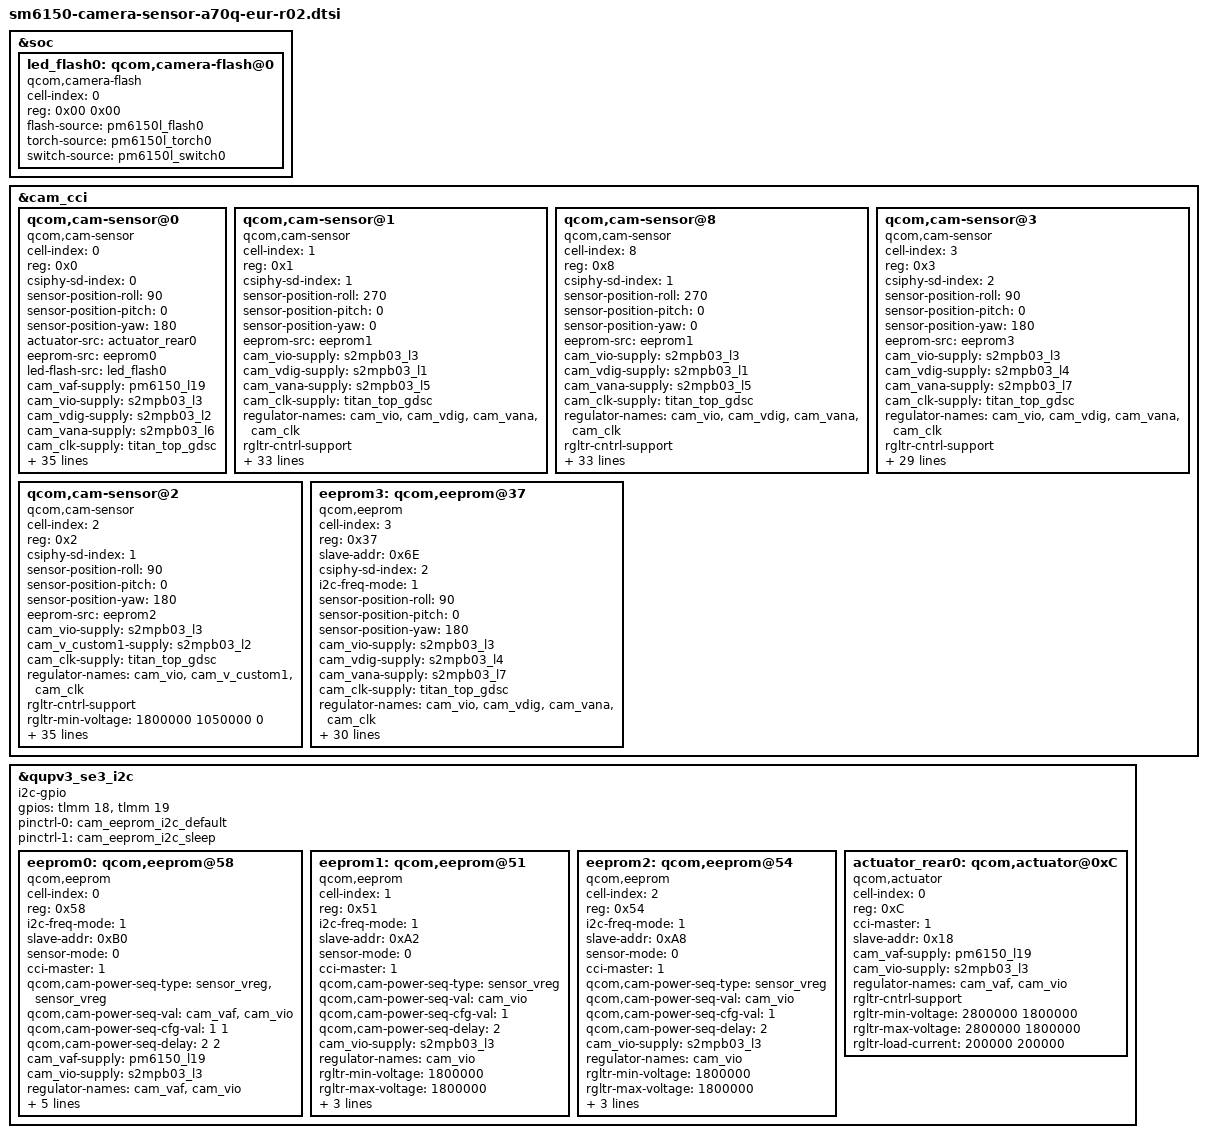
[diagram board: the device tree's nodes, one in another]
&soc {
        led_flash0: qcom,camera-flash@0 {
              cell-index = <0>;
              reg = <0x00 0x00>;
              compatible = "qcom,camera-flash";
              flash-source = <&pm6150l_flash0>;
              torch-source = <&pm6150l_torch0>;
              switch-source = <&pm6150l_switch0>;		
              status = "ok";
        };
};

&cam_cci{
		qcom,cam-sensor@0 {
			cell-index = <0>;
			compatible = "qcom,cam-sensor";
			reg = <0x0>;
			csiphy-sd-index = <0>;
			sensor-position-roll = <90>;
			sensor-position-pitch = <0>;
			sensor-position-yaw = <180>;
			actuator-src = <&actuator_rear0>;
			eeprom-src = <&eeprom0>;  
			led-flash-src = <&led_flash0>;
			cam_vaf-supply = <&pm6150_l19>;
			cam_vio-supply = <&s2mpb03_l3>;
			cam_vdig-supply = <&s2mpb03_l2>;
			cam_vana-supply = <&s2mpb03_l6>;
			cam_clk-supply = <&titan_top_gdsc>; 
			regulator-names = "cam_vaf", "cam_vio", "cam_vdig", "cam_vana", "cam_clk";
			rgltr-cntrl-support;
			rgltr-min-voltage = <2800000 1800000 1050000 2800000 0>;
			rgltr-max-voltage = <2800000 1800000 1050000 2800000 0>;
			rgltr-load-current = <200000 200000 200000 200000 0>;
			gpio-no-mux = <0>;
			pinctrl-names = "cam_default", "cam_suspend";
			pinctrl-0 = <&cam_sensor_mclk_0_active &cam_sensor_rear_active>;
			pinctrl-1 = <&cam_sensor_mclk_0_suspend &cam_sensor_rear_suspend>;
			gpios = <&tlmm 28 0>,
					<&tlmm 47 0>;
			gpio-reset = <1>;
			gpio-req-tbl-num = <0 1>;
			gpio-req-tbl-flags = <1 0>;
			gpio-req-tbl-label = "CAMIF_MCLK0", "CAM_RESET0";

			sensor-mode = <0>;
			cci-master = <0>;
			status = "ok";
			clocks = <&clock_camcc CAM_CC_MCLK0_CLK>;
			clock-names = "cam_clk";
			clock-cntl-level = "turbo";
			clock-rates = <24000000>;

			cam,isp = <0>;                  // 0 : INT , 1 : EXT , 2 : SOC
			cam,cal_memory = <2>;           // 0 : N , 1 : FROM , 2 : EEPROM , 3 : OTP
			cam,read_version = <0>;         // 0 : SYSFS , 1 : CAMON
			cam,core_voltage = <0>;         // 0 : N , 1 : Y
			cam,upgrade = <0>;              // 0 : N , 1 : SYSFS , 2 : CAMON
			cam,fw_write = <0>;             // 0 : N , 1 : OS , 2 : SD , 3 : ALL
			cam,fw_dump = <0>;              // 0 : N , 1 : Y
			cam,companion_chip = <0>;       // 0 : N , 1 : Y
			cam,ois = <0>;                  // 0 : N , 1 : Y
			cam,dual_open = <0>;            // 0 : N , 1 : Y
			cam,valid = <1>;                // 0 : N , 1 : Y
        };
		qcom,cam-sensor@1 {
			cell-index = <1>;
			compatible = "qcom,cam-sensor";
			reg = <0x1>;
			csiphy-sd-index = <1>;
			sensor-position-roll = <270>;
			sensor-position-pitch = <0>;
			sensor-position-yaw = <0>;
			eeprom-src = <&eeprom1>;
			cam_vio-supply = <&s2mpb03_l3>;
			cam_vdig-supply = <&s2mpb03_l1>;
			cam_vana-supply = <&s2mpb03_l5>;
			cam_clk-supply = <&titan_top_gdsc>; 
			regulator-names = "cam_vio", "cam_vdig", "cam_vana", "cam_clk";
			rgltr-cntrl-support;
			rgltr-min-voltage = <1800000 1050000 2800000 0>;
			rgltr-max-voltage = <1800000 1050000 2800000 0>;
			rgltr-load-current = <200000 200000 200000 0>;
			gpio-no-mux = <0>;
			pinctrl-names = "cam_default", "cam_suspend";
			pinctrl-0 = <&cam_sensor_mclk_1_active &cam_sensor_front_active &cam_sensor_mipi_sw_active>;
			pinctrl-1 = <&cam_sensor_mclk_1_suspend &cam_sensor_front_suspend &cam_sensor_mipi_sw_suspend>;
			gpios = <&tlmm 29 0>,
					<&tlmm 45 0>,
					<&tlmm 49 0>;
			gpio-reset = <1>;
			gpio-custom1 = <2>;
			gpio-req-tbl-num = <0 1 2>;
			gpio-req-tbl-flags = <1 0 0>;
			gpio-req-tbl-label = "CAMIF_MCLK1", "CAM_RESET1", "CAM_CUSTOM1";

			sensor-mode = <0>;
			cci-master = <1>;
			status = "ok";
			clocks = <&clock_camcc CAM_CC_MCLK1_CLK>;
			clock-names = "cam_clk";
			clock-cntl-level = "turbo";
			clock-rates = <24000000>;

			cam,isp = <0>;                  // 0 : INT , 1 : EXT , 2 : SOC
			cam,cal_memory = <2>;           // 0 : N , 1 : FROM , 2 : EEPROM , 3 : OTP
			cam,read_version = <0>;         // 0 : SYSFS , 1 : CAMON
			cam,core_voltage = <0>;         // 0 : N , 1 : Y
			cam,upgrade = <0>;              // 0 : N , 1 : SYSFS , 2 : CAMON
			cam,fw_write = <0>;             // 0 : N , 1 : OS , 2 : SD , 3 : ALL
			cam,fw_dump = <0>;              // 0 : N , 1 : Y
			cam,companion_chip = <0>;       // 0 : N , 1 : Y
			cam,ois = <0>;                  // 0 : N , 1 : Y
			cam,dual_open = <0>;            // 0 : N , 1 : Y
			cam,valid = <1>;                // 0 : N , 1 : Y
        };

		qcom,cam-sensor@8 {
			cell-index = <8>;
			compatible = "qcom,cam-sensor";
			reg = <0x8>;
			csiphy-sd-index = <1>;
			sensor-position-roll = <270>;
			sensor-position-pitch = <0>;
			sensor-position-yaw = <0>;
			eeprom-src = <&eeprom1>;
			cam_vio-supply = <&s2mpb03_l3>;
			cam_vdig-supply = <&s2mpb03_l1>;
			cam_vana-supply = <&s2mpb03_l5>;
			cam_clk-supply = <&titan_top_gdsc>; 
			regulator-names = "cam_vio", "cam_vdig", "cam_vana", "cam_clk";
			rgltr-cntrl-support;
			rgltr-min-voltage = <1800000 1050000 2800000 0>;
			rgltr-max-voltage = <1800000 1050000 2800000 0>;
			rgltr-load-current = <200000 200000 200000 0>;
			gpio-no-mux = <0>;
			pinctrl-names = "cam_default", "cam_suspend";
			pinctrl-0 = <&cam_sensor_mclk_1_active &cam_sensor_front_active &cam_sensor_mipi_sw_active>;
			pinctrl-1 = <&cam_sensor_mclk_1_suspend &cam_sensor_front_suspend &cam_sensor_mipi_sw_suspend>;
			gpios = <&tlmm 29 0>,
					<&tlmm 45 0>,
					<&tlmm 49 0>;
			gpio-reset = <1>;
			gpio-custom1 = <2>;
			gpio-req-tbl-num = <0 1 2>;
			gpio-req-tbl-flags = <1 0 0>;
			gpio-req-tbl-label = "CAMIF_MCLK1", "CAM_RESET1", "CAM_CUSTOM1";

			sensor-mode = <0>;
			cci-master = <1>;
			status = "ok";
			clocks = <&clock_camcc CAM_CC_MCLK1_CLK>;
			clock-names = "cam_clk";
			clock-cntl-level = "turbo";
			clock-rates = <24000000>;

			cam,isp = <0>;                  // 0 : INT , 1 : EXT , 2 : SOC
			cam,cal_memory = <2>;           // 0 : N , 1 : FROM , 2 : EEPROM , 3 : OTP
			cam,read_version = <0>;         // 0 : SYSFS , 1 : CAMON
			cam,core_voltage = <0>;         // 0 : N , 1 : Y
			cam,upgrade = <0>;              // 0 : N , 1 : SYSFS , 2 : CAMON
			cam,fw_write = <0>;             // 0 : N , 1 : OS , 2 : SD , 3 : ALL
			cam,fw_dump = <0>;              // 0 : N , 1 : Y
			cam,companion_chip = <0>;       // 0 : N , 1 : Y
			cam,ois = <0>;                  // 0 : N , 1 : Y
			cam,dual_open = <0>;            // 0 : N , 1 : Y
			cam,valid = <1>;                // 0 : N , 1 : Y
        };
		
		qcom,cam-sensor@3 {
			cell-index = <3>;
			compatible = "qcom,cam-sensor";
			reg = <0x3>;
			csiphy-sd-index = <2>;
			sensor-position-roll = <90>;
			sensor-position-pitch = <0>;
			sensor-position-yaw = <180>;
			eeprom-src = <&eeprom3>;
			cam_vio-supply = <&s2mpb03_l3>;
			cam_vdig-supply = <&s2mpb03_l4>;
			cam_vana-supply = <&s2mpb03_l7>;
			cam_clk-supply = <&titan_top_gdsc>; 
			regulator-names = "cam_vio", "cam_vdig", "cam_vana", "cam_clk";
			rgltr-cntrl-support;
			rgltr-min-voltage = <1800000 1200000 2800000 0>;
			rgltr-max-voltage = <1800000 1200000 2800000 0>;
			rgltr-load-current = <200000 200000 200000 0>;
			gpio-no-mux = <0>;
			pinctrl-names = "cam_default", "cam_suspend";
			pinctrl-0 = <&cam_sensor_mclk_2_active &cam_sensor_rear2_active>;
			pinctrl-1 = <&cam_sensor_mclk_2_suspend &cam_sensor_rear2_suspend>;
			gpios = <&tlmm 30 0>,
					<&tlmm 46 0>;
			gpio-reset = <1>;
			gpio-req-tbl-num = <0 1>;
			gpio-req-tbl-flags = <1 0>;
			gpio-req-tbl-label = "CAMIF_MCLK2", "CAM_RESET2";

			sensor-mode = <0>;
			cci-master = <1>;
			status = "ok";
			clocks = <&clock_camcc CAM_CC_MCLK2_CLK>;
			clock-names = "cam_clk";
			clock-cntl-level = "turbo";
			clock-rates = <24000000>;

			cam,isp = <0>;                  // 0 : INT , 1 : EXT , 2 : SOC
			cam,cal_memory = <2>;           // 0 : N , 1 : FROM , 2 : EEPROM , 3 : OTP
			cam,read_version = <0>;         // 0 : SYSFS , 1 : CAMON
			cam,core_voltage = <0>;         // 0 : N , 1 : Y
			cam,upgrade = <0>;              // 0 : N , 1 : SYSFS , 2 : CAMON
			cam,fw_write = <0>;             // 0 : N , 1 : OS , 2 : SD , 3 : ALL
			cam,fw_dump = <0>;              // 0 : N , 1 : Y
			cam,companion_chip = <0>;       // 0 : N , 1 : Y
			cam,ois = <0>;                  // 0 : N , 1 : Y
			cam,dual_open = <0>;            // 0 : N , 1 : Y
			cam,valid = <1>;                // 0 : N , 1 : Y
        };

		qcom,cam-sensor@2 { /* 4HA */
			cell-index = <2>;
			compatible = "qcom,cam-sensor";
			reg = <0x2>;
			csiphy-sd-index = <1>;		
			sensor-position-roll = <90>;
			sensor-position-pitch = <0>;
			sensor-position-yaw = <180>;
			eeprom-src = <&eeprom2>;		
			cam_vio-supply = <&s2mpb03_l3>;
			cam_v_custom1-supply = <&s2mpb03_l2>;
			cam_clk-supply = <&titan_top_gdsc>;
			regulator-names = "cam_vio", "cam_v_custom1", "cam_clk";
			rgltr-cntrl-support;
			rgltr-min-voltage = <1800000 1050000 0>;
			rgltr-max-voltage = <1800000 1050000 0>;
			rgltr-load-current = <200000 200000 0>;
			gpio-no-mux = <0>;
			pinctrl-names = "cam_default", "cam_suspend";
			pinctrl-0 = <&cam_sensor_mclk_3_active &cam_sensor_rear3sw_active &cam_rear3_pwr_active &cam_sensor_mipi_sw_active>;
			pinctrl-1 = <&cam_sensor_mclk_3_suspend &cam_sensor_rear3sw_suspend &cam_rear3_pwr_suspend &cam_sensor_mipi_sw_suspend>;
			gpios = <&tlmm 31 0>, /* MCLK */
					<&tlmm 100 0>, /* RESET */
					<&tlmm 95 0>, /* DVDD,AVDD ENABLE */
					<&tlmm 49 0>; /* MIPI SW SEL BETWEEN FRONT AND RCAM3 */
			gpio-reset = <1>;
			gpio-vana = <2>;
			gpio-custom1 = <3>;
			gpio-req-tbl-num = <0 1 2 3>;
			gpio-req-tbl-flags = <1 0 0 0>;
			gpio-req-tbl-label = "CAMIF_MCLK3", "CAM_RESET3", "CAM_VANA", "CAM_CUSTOM1";

			sensor-mode = <0>;
			cci-master = <1>;
			status = "ok";
			clocks = <&clock_camcc CAM_CC_MCLK3_CLK>;
			clock-names = "cam_clk";
			clock-cntl-level = "turbo";
			clock-rates = <24000000>;

			cam,isp = <0>;                  // 0 : INT , 1 : EXT , 2 : SOC
			cam,cal_memory = <2>;           // 0 : N , 1 : FROM , 2 : EEPROM , 3 : OTP
			cam,read_version = <0>;         // 0 : SYSFS , 1 : CAMON
			cam,core_voltage = <0>;         // 0 : N , 1 : Y
			cam,upgrade = <0>;              // 0 : N , 1 : SYSFS , 2 : CAMON
			cam,fw_write = <0>;             // 0 : N , 1 : OS , 2 : SD , 3 : ALL
			cam,fw_dump = <0>;              // 0 : N , 1 : Y
			cam,companion_chip = <0>;       // 0 : N , 1 : Y
			cam,ois = <0>;                  // 0 : N , 1 : Y
			cam,dual_open = <0>;            // 0 : N , 1 : Y
			cam,valid = <1>;
	};

        eeprom3: qcom,eeprom@37 {
                cell-index = <3>;
                compatible = "qcom,eeprom";
                reg = <0x37>;
                slave-addr = <0x6E>;//QUP use 0x6E
                csiphy-sd-index = <2>;
                i2c-freq-mode = <1>;

                sensor-position-roll = <90>;
                sensor-position-pitch = <0>;
                sensor-position-yaw = <180>;
                //eeprom-src = <&eeprom2>;
                cam_vio-supply = <&s2mpb03_l3>;
                cam_vdig-supply = <&s2mpb03_l4>;
                cam_vana-supply = <&s2mpb03_l7>;
                cam_clk-supply = <&titan_top_gdsc>; 
                regulator-names = "cam_vio", "cam_vdig", "cam_vana", "cam_clk";
                rgltr-cntrl-support;
                rgltr-min-voltage = <1800000 1200000 2800000 0>;
                rgltr-max-voltage = <1800000 1200000 2800000 0>;
                rgltr-load-current = <200000 200000 200000 0>;
                gpio-no-mux = <0>;
                pinctrl-names = "cam_default", "cam_suspend";
                pinctrl-0 = <&cam_sensor_mclk_2_active &cam_sensor_rear2_active>;
                pinctrl-1 = <&cam_sensor_mclk_2_suspend &cam_sensor_rear2_suspend>;
                gpios = <&tlmm 30 0>,
                        <&tlmm 46 0>;
                gpio-reset = <1>;
                gpio-req-tbl-num = <0 1>;
                gpio-req-tbl-flags = <1 0>;
                gpio-req-tbl-label = "CAMIF_MCLK2", "CAM_RESET2";

                sensor-mode = <0>;
                cci-master = <1>;
                status = "ok";
                clocks = <&clock_camcc CAM_CC_MCLK2_CLK>;
                clock-names = "cam_clk";
                clock-cntl-level = "turbo";
                clock-rates = <24000000>;

                cam,isp = <0>;                  // 0 : INT , 1 : EXT , 2 : SOC
                cam,cal_memory = <2>;           // 0 : N , 1 : FROM , 2 : EEPROM , 3 : OTP
                cam,read_version = <0>;         // 0 : SYSFS , 1 : CAMON
                cam,core_voltage = <0>;         // 0 : N , 1 : Y
                cam,upgrade = <0>;              // 0 : N , 1 : SYSFS , 2 : CAMON
                cam,fw_write = <0>;             // 0 : N , 1 : OS , 2 : SD , 3 : ALL
                cam,fw_dump = <0>;              // 0 : N , 1 : Y
                cam,companion_chip = <0>;       // 0 : N , 1 : Y
                cam,ois = <0>;                  // 0 : N , 1 : Y
                cam,dual_open = <0>;            // 0 : N , 1 : Y
                cam,valid = <1>;                // 0 : N , 1 : Y
        };
};

&qupv3_se3_i2c{
	status = "ok";
	compatible = "i2c-gpio";
	gpios = <&tlmm 18 0
                 &tlmm 19 0 >;
	pinctrl-names = "cam_default", "cam_suspend";
	pinctrl-0 = <&cam_eeprom_i2c_default>;
	pinctrl-1 = <&cam_eeprom_i2c_sleep>;

	eeprom0: qcom,eeprom@58 {
                cell-index = <0>;
                reg = <0x58>; //QUP use 0xB0
                compatible = "qcom,eeprom";
                i2c-freq-mode = <1>;
                slave-addr = <0xB0>;
                sensor-mode = <0>;
                cci-master = <1>;

                qcom,cam-power-seq-type = "sensor_vreg", "sensor_vreg";
                qcom,cam-power-seq-val = "cam_vaf", "cam_vio";
                qcom,cam-power-seq-cfg-val = <1 1>;
                qcom,cam-power-seq-delay = <2 2>;

                cam_vaf-supply = <&pm6150_l19>;
                cam_vio-supply = <&s2mpb03_l3>;
                regulator-names = "cam_vaf", "cam_vio";
                rgltr-min-voltage = <2800000 1800000>;
                rgltr-max-voltage = <2800000 1800000>;
                rgltr-load-current = <200000 200000>;

                sensor-position = <0>;
                rgltr-cntrl-support;
	};
	
	eeprom1: qcom,eeprom@51 {
                cell-index = <1>;
                reg = <0x51>;//QUP use 0xA2
                compatible = "qcom,eeprom";
                i2c-freq-mode = <1>;
                slave-addr = <0xA2>;
                sensor-mode = <0>;
                cci-master = <1>;

                qcom,cam-power-seq-type = "sensor_vreg";
                qcom,cam-power-seq-val = "cam_vio";
                qcom,cam-power-seq-cfg-val = <1>;
                qcom,cam-power-seq-delay = <2>;

                cam_vio-supply = <&s2mpb03_l3>;
                regulator-names = "cam_vio";
                rgltr-min-voltage = <1800000>;
                rgltr-max-voltage = <1800000>;
                rgltr-load-current = <200000>;

                sensor-position = <1>;
                rgltr-cntrl-support;
	};

	eeprom2: qcom,eeprom@54 {
                cell-index = <2>;
                reg = <0x54>;
                compatible = "qcom,eeprom";
                i2c-freq-mode = <1>;
                slave-addr = <0xA8>;//QUP use 0xA8
                sensor-mode = <0>;
                cci-master = <1>;

                qcom,cam-power-seq-type = "sensor_vreg";
                qcom,cam-power-seq-val = "cam_vio";
                qcom,cam-power-seq-cfg-val = <1>;
                qcom,cam-power-seq-delay = <2>;

                cam_vio-supply = <&s2mpb03_l3>;
                regulator-names = "cam_vio";
                rgltr-min-voltage = <1800000>;
                rgltr-max-voltage = <1800000>;
                rgltr-load-current = <200000>;

                sensor-position = <0>;
                rgltr-cntrl-support;
	};

	actuator_rear0: qcom,actuator@0xC {
                cell-index = <0>;
                reg = <0xC>;
                cci-master = <1>;
                slave-addr = <0x18>;
                compatible = "qcom,actuator";
                cam_vaf-supply = <&pm6150_l19>;
                cam_vio-supply = <&s2mpb03_l3>;
                regulator-names = "cam_vaf", "cam_vio";
                rgltr-cntrl-support;
                rgltr-min-voltage = <2800000 1800000>;
                rgltr-max-voltage = <2800000 1800000>;
                rgltr-load-current = <200000 200000>;
	};
};
